# APM32F105xx register map
File version: 1.0
CPU: CM3 r2p1, little endian, no MPU, no FPU, 4 interrupt priority bits
Registers are 32-bit, read-write, reset 0x0 unless marked. A register's access mark holds for its fields unless they carry their own. Offsets are from the block's base; [hi:lo] are bit positions; 'fields as' and 'values as' point back to an identical list.

## I2C1 — Inter integrated circuit 1
Base 0x40005400
Same registers: I2C2 0x40005800
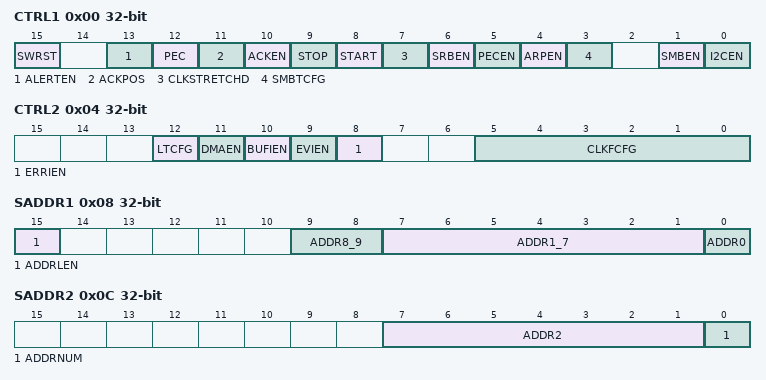
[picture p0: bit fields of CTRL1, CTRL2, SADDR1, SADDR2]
0x00 CTRL1 — Control register 1
  [15] SWRST — Software reset
  [13] ALERTEN — SMBus alert
  [12] PEC — Packet error checking
  [11] ACKPOS — Acknowledge/PEC Position (for data reception)
  [10] ACKEN — Acknowledge enable
  [9] STOP — Stop generation
  [8] START — Start generation
  [7] CLKSTRETCHD — Clock stretching disable (Slave mode)
  [6] SRBEN — General call enable
  [5] PECEN — PEC enable
  [4] ARPEN — ARP enable
  [3] SMBTCFG — SMBus type
  [1] SMBEN — SMBus mode
  [0] I2CEN — Peripheral enable
0x04 CTRL2 — Control register 2
  [12] LTCFG — DMA last transfer
  [11] DMAEN — DMA requests enable
  [10] BUFIEN — Buffer interrupt enable
  [9] EVIEN — Event interrupt enable
  [8] ERRIEN — Error interrupt enable
  [5:0] CLKFCFG — Peripheral clock frequency
0x08 SADDR1 — Own address register 1
  [15] ADDRLEN — Address Length Configure
  [9:8] ADDR8_9 — Interface address
  [7:1] ADDR1_7 — Interface address
  [0] ADDR0 — Interface address
0x0C SADDR2 — Own address register 2
  [7:1] ADDR2 — Interface address
  [0] ADDRNUM — Dual addressing mode enable
0x10 DATA
  [7:0] DATA — 8-bit data register
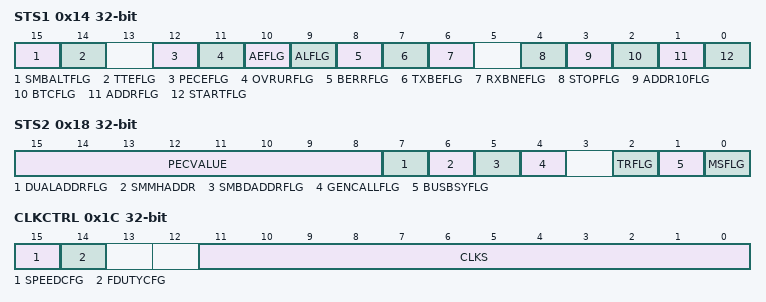
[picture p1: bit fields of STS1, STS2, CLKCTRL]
0x14 STS1 access per field — Status register 1
  [15] SMBALTFLG rw — SMBus alert
  [14] TTEFLG rw — Timeout or Tlow error
  [12] PECEFLG rw — PEC Error in reception
  [11] OVRURFLG rw — Overrun/Underrun
  [10] AEFLG rw — Acknowledge failure
  [9] ALFLG rw — Arbitration lost (master mode)
  [8] BERRFLG rw — Bus error
  [7] TXBEFLG ro — Data register empty (transmitters)
  [6] RXBNEFLG ro — Data register not empty (receivers)
  [4] STOPFLG ro — Stop detection (slave mode)
  [3] ADDR10FLG ro — 10-bit header sent (Master mode)
  [2] BTCFLG ro — Byte transfer finished
  [1] ADDRFLG ro — Address sent (master mode)/matched (slave mode)
  [0] STARTFLG ro — Start bit (Master mode)
0x18 STS2 ro — Status register 2
  [15:8] PECVALUE — acket error checking register
  [7] DUALADDRFLG — Dual flag (Slave mode)
  [6] SMMHADDR — SMBus host header (Slave mode)
  [5] SMBDADDRFLG — SMBus device default address (Slave mode)
  [4] GENCALLFLG — General call address (Slave mode)
  [2] TRFLG — Transmitter/receiver
  [1] BUSBSYFLG — Bus busy
  [0] MSFLG — Master/slave
0x1C CLKCTRL — Clock control register
  [15] SPEEDCFG — I2C master mode selection
  [14] FDUTYCFG — Fast mode duty cycle
  [11:0] CLKS — Clock control register in Fast/Standard mode (Master mode)
0x20 RISETMAX reset 0x2
  [5:0] RISETMAX — Maximum rise time in Fast/Standard mode (Master mode)
0x100 SWITCH reset 0x2 — I2C Switching register
  [0] SWITCH — I2C Switching

## SCI2C1 — Inter integrated circuit 1
Base 0x40005400; alternate view of I2C1
Same registers: SCI2C2 0x40005800 (alternate view of I2C2)
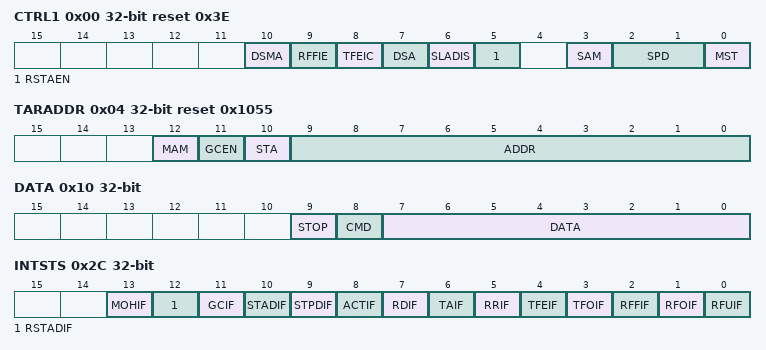
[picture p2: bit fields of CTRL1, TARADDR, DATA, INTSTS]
0x00 CTRL1 reset 0x3E — Control register 1
  [10] DSMA, [9] RFFIE, [8] TFEIC, [7] DSA, [6] SLADIS, [5] RSTAEN, [3] SAM, [2:1] SPD, [0] MST
0x04 TARADDR reset 0x1055 — Target address register
  [12] MAM, [11] GCEN, [10] STA, [9:0] ADDR
0x08 SLAADDR reset 0x55 — Slave address register
  [9:0] ADDR
0x0C HSMC reset 0x7 — High speed master code register
  [3:0] HSMC
0x10 DATA
  [9] STOP
  [8] CMD
  [7:0] DATA — 8-bit data register
0x14 SSCHC reset 0x190 — Standard speed clock high counter register
  [15:0] CNT
0x18 SSCLC reset 0x1D6 — Standard speed clock low counter register
  [15:0] CNT
0x1C FSCHC reset 0x3C — Fast speed clock high counter register
  [15:0] CNT
0x20 FSCLC reset 0x82 — Fast speed clock low counter register
  [15:0] CNT
0x24 HSCHC reset 0x6 — High speed clock high counter
  [15:0] CNT
0x28 HSCLC reset 0x10 — High speed clock low counter register
  [15:0] CNT
0x2C INTSTS — Interrupt status register
  [13] MOHIF, [12] RSTADIF, [11] GCIF, [10] STADIF, [9] STPDIF, [8] ACTIF, [7] RDIF, [6] TAIF, [5] RRIF, [4] TFEIF, [3] TFOIF, [2] RFFIF, [1] RFOIF, [0] RFUIF
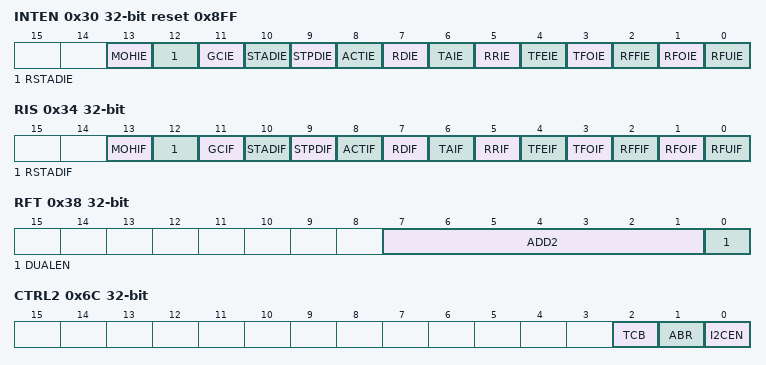
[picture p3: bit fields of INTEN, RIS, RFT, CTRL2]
0x30 INTEN reset 0x8FF — Interrupt enable register
  [13] MOHIE, [12] RSTADIE, [11] GCIE, [10] STADIE, [9] STPDIE, [8] ACTIE, [7] RDIE, [6] TAIE, [5] RRIE, [4] TFEIE, [3] TFOIE, [2] RFFIE, [1] RFOIE, [0] RFUIE
0x34 RIS — Raw interrupt status register
  fields as INTSTS
0x38 RFT — Reception FIFO threshold register
  [7:1] ADD2 — Interface address
  [0] DUALEN — Dual addressing mode enable
0x3C TFT — Transmission FIFO threshold register
  [7:0] RFT
0x40 INTCLR — Interruption clear register
  [7:0] TFT
0x44 RFUIC ro — Reception FIFO underflow interruption clear register
  [0] INTCLR
0x48 RFOIC ro — Reception FIFO overflow interruption clear register
  [0] RFUIC
0x4C TFOIC ro — Transmission FIFO overflow interruption clear register
  [0] RFOIC
0x50 RRIC ro — Reception request interruption clear register
  [0] TFOIC
0x54 TAIC ro — Transmission abort interruption clear register
  [0] RRIC
0x58 RDIC ro — Receive done interruption clear register
  [0] RDIC
0x5C AIC — Activity interruption clear register
  [0] AIC
0x60 STPDIC — Stop detection interruption clear register
  [5:0] STPDIC
0x64 STADIC — Start detection interruption clear register
  [0] STADIC
0x68 GCIC — General call interruption clear register
  [5:0] GCIC
0x6C CTRL2 — Control register 2
  [2] TCB, [1] ABR, [0] I2CEN
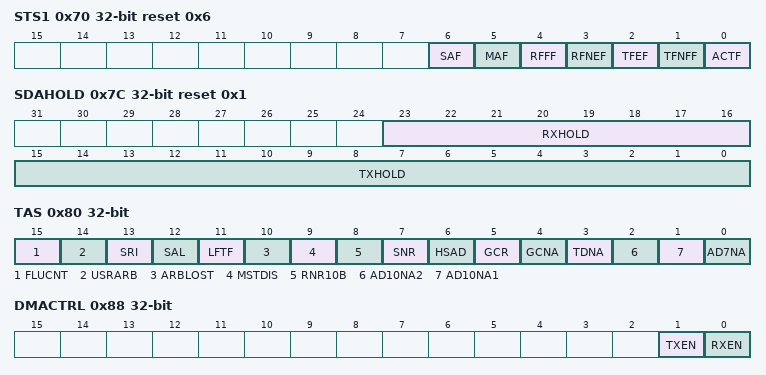
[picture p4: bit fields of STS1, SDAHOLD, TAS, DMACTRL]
0x70 STS1 reset 0x6 — Status register 1
  [6] SAF, [5] MAF, [4] RFFF, [3] RFNEF, [2] TFEF, [1] TFNFF, [0] ACTF
0x74 TFL — Transmission FIFO level
  [0] TFL
0x78 RFL — Reception FIFO level
  [5:0] RFL
0x7C SDAHOLD reset 0x1 — SDA hold time length register
  [23:16] RXHOLD, [15:0] TXHOLD
0x80 TAS — Transmission abort source register
  [15] FLUCNT, [14] USRARB, [13] SRI, [12] SAL, [11] LFTF, [10] ARBLOST, [9] MSTDIS, [8] RNR10B, [7] SNR, [6] HSAD, [5] GCR, [4] GCNA, [3] TDNA, [2] AD10NA2, [1] AD10NA1, [0] AD7NA
0x84 SDNO — Slave data NACK only register
  [0] NACK
0x88 DMACTRL — DMA control register
  [1] TXEN, [0] RXEN
0x8C DTDL — DMA transmission data level register
  [0] DTDL
0x90 DRDL — DMA teception data level register
  [5:0] DRDL
0x94 SDADLY reset 0x64 — SDA delay register
  [0] SDADLY
0x98 GCA reset 0x1 — Genernal call ACK register
  [5:0] GCA
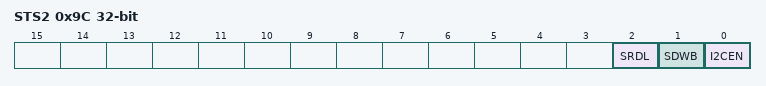
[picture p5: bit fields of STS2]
0x9C STS2 — Status register2
  [2] SRDL, [1] SDWB, [0] I2CEN
0xA0 LSSSL reset 0x5 — Low speed spike suppression limit
  [5:0] LSSSL
0xA4 HSSSL reset 0x1 — High speed spike suppression limit
  [0] HSSSL
0x100 SW — Switch register
  [0] SW
